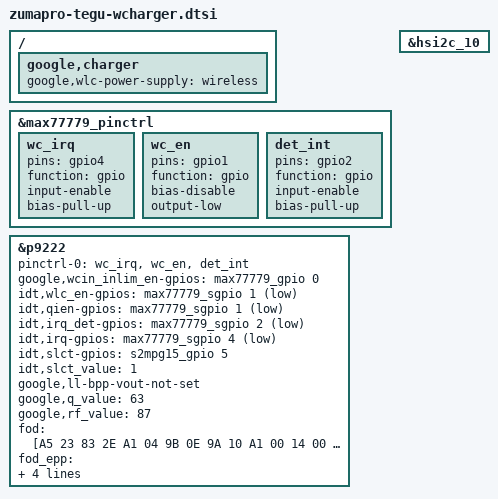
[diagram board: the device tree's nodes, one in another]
// SPDX-License-Identifier: GPL-2.0-only
/*
 * Wireless Charger device tree entries.
 *
 * Copyright 2024 Google LLC
 */

#include <arm64/exynos/exynos-pinctrl.h>
#include <dt-bindings/interrupt-controller/irq.h>

/ {
	fragment@wlc {
		target-path = "/";
		__overlay__ {
			google,charger {
				google,wlc-power-supply = "wireless";
			};
		};
	};
};

&max77779_pinctrl {
	/* QI_INT_ODL Wireless Charger Interrupt */
	wc_irq: wc_irq {
		pins = "gpio4";
		function = "gpio";
		input-enable;
		bias-pull-up;
	};

	/* QI_RX_COMM_EN_L Wireless Charger Enable */
	wc_en: wc_en {
		pins = "gpio1";
		function = "gpio";
		bias-disable;
		output-low;
	};

	/* QI_PDET_GPOD6 */
	det_int: det_int {
		pins = "gpio2";
		function = "gpio";
		input-enable;
		bias-pull-up;
	};
};

&hsi2c_10 {
	#address-cells = <1>;
	#size-cells = <0>;

	#include "zuma-wcharger-p9222.dtsi"
};

&p9222 {
	status = "okay";
	pinctrl-0 = <&wc_irq &wc_en &det_int>;

	google,wcin_inlim_en-gpios = <&max77779_gpio 0 GPIO_ACTIVE_HIGH>;
	idt,wlc_en-gpios = <&max77779_sgpio 1 GPIO_ACTIVE_LOW>; /* QI_EN_L */
	idt,qien-gpios = <&max77779_sgpio 1 GPIO_ACTIVE_LOW>; /* QI_EN_L */
	idt,irq_det-gpios = <&max77779_sgpio 2 GPIO_ACTIVE_LOW>; /* QI_PDET_OD_L */
	idt,irq-gpios = <&max77779_sgpio 4 GPIO_ACTIVE_LOW>; /* QI_INT_ODL */
	idt,slct-gpios = <&s2mpg15_gpio 5 GPIO_ACTIVE_HIGH>; /* QI_BPP_EPP_SLCT */
	idt,slct_value = <1>;
	google,ll-bpp-vout-not-set;
	google,q_value = <63>;
	google,rf_value = <87>;
	fod = [A5 23 83 2E A1 04 9B 0E 9A 10 A1 00 14 00 00 28];
	fod_epp = [98 1F 7E 42 99 F9 92 0F 99 E0 9F C9 14 00 00 25];
	fod_gpp = [98 28 7E 57 99 FA 92 10 99 FF 9F F1 14 00 00 25];

	/* High dissipation adapter */
	google,hda-tz-wlc;
};
